# STM32L4A6xx register map
File version: 1.0
Registers are 32-bit, read-write, reset 0x0 unless marked. A register's access mark holds for its fields unless they carry their own. Offsets are from the block's base; [hi:lo] are bit positions; {n}, {i} and the like mark numbered series.

## DCMI
Base 0x50050000
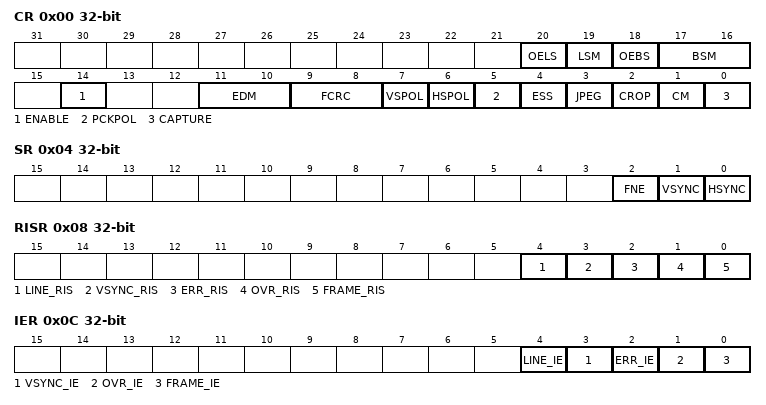
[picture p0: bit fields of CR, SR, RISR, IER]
0x00 CR — DCMI control register
  [20] OELS — DCMI Odd/Even Line Select (Line Select Start)
  [19] LSM — DCMI Line Select mode
  [18] OEBS — DCMI Odd/Even Byte Select (Byte Select Start)
  [17:16] BSM — DCMI Byte Select mode BSM[1:0]
  [14] ENABLE — DCMI DCMI enable
  [11:10] EDM — DCMI Extended data mode EDM[1:0]
  [9:8] FCRC — DCMI Frame capture rate control FCRC[1:0]
  [7] VSPOL — DCMI Vertical synchronization polarity
  [6] HSPOL — DCMI Horizontal synchronization polarity
  [5] PCKPOL — DCMI Pixel clock polarity
  [4] ESS — DCMI Embedded synchronization select
  [3] JPEG — DCMI JPEG format
  [2] CROP — DCMI Crop feature
  [1] CM — DCMI Capture mode
  [0] CAPTURE — DCMI Capture enable
0x04 SR — DCMI status register
  [2] FNE — DCMI FIFO not empty
  [1] VSYNC
  [0] HSYNC
0x08 RISR — DCMI raw interrupt status register
  [4] LINE_RIS — DCMI Line raw interrupt status
  [3] VSYNC_RIS — DCMI VSYNC raw interrupt status
  [2] ERR_RIS — DCMI Synchronization error raw interrupt status
  [1] OVR_RIS — DCMI Overrun raw interrupt status
  [0] FRAME_RIS — DCMI Capture complete raw interrupt status
0x0C IER — DCMI interrupt enable register
  [4] LINE_IE — DCMI Line interrupt enable
  [3] VSYNC_IE — DCMI VSYNC interrupt enable
  [2] ERR_IE — DCMI Synchronization error interrupt enable
  [1] OVR_IE — DCMI Overrun interrupt enable
  [0] FRAME_IE — DCMI Capture complete interrupt enable
0x0C IER_ALT (alternate view of IER) — DCMI interrupt enable register
  [4:0] INT_IE
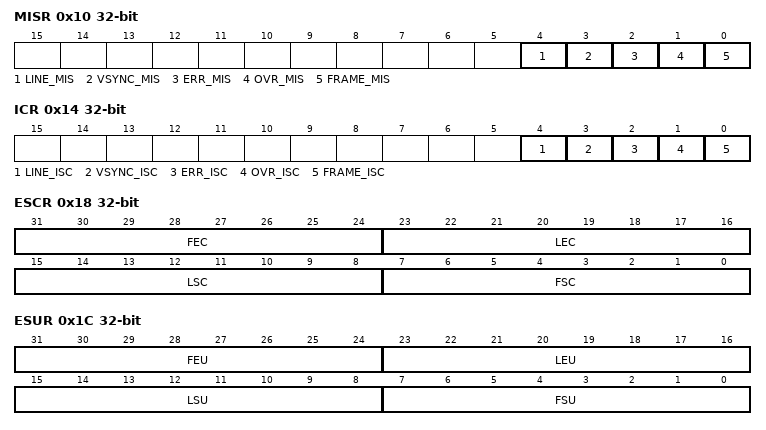
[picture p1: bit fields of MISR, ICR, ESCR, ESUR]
0x10 MISR — DCMI masked interrupt status register
  [4] LINE_MIS — DCMI Line masked interrupt status
  [3] VSYNC_MIS — DCMI VSYNC masked interrupt status
  [2] ERR_MIS — DCMI Synchronization error masked interrupt status
  [1] OVR_MIS — DCMI Overrun masked interrupt status
  [0] FRAME_MIS — DCMI Capture complete masked interrupt status
0x14 ICR — DCMI interrupt clear register
  [4] LINE_ISC — DCMI line interrupt status clear
  [3] VSYNC_ISC — DCMI Vertical synch interrupt status clear
  [2] ERR_ISC — DCMI Synchronization error interrupt status clear
  [1] OVR_ISC — DCMI Overrun interrupt status clear
  [0] FRAME_ISC — DCMI Capture complete interrupt status clear
0x18 ESCR — DCMI embedded synchronization code register
  [31:24] FEC — DCMI Frame end delimiter code FEC[7:0]
  [23:16] LEC — DCMI Line end delimiter code LEC[7:0]
  [15:8] LSC — DCMI Line start delimiter code LSC[7:0]
  [7:0] FSC — DCMI Frame start delimiter code FSC[7:0]
0x1C ESUR — DCMI embedded synchronization unmask register
  [31:24] FEU — DCMI Frame end delimiter unmask FEU[7:0]
  [23:16] LEU — DCMI Line end delimiter unmask LEU[7:0]
  [15:8] LSU — DCMI Line start delimiter unmask LSU[7:0]
  [7:0] FSU — DCMI Frame start delimiter unmask FSU[7:0]
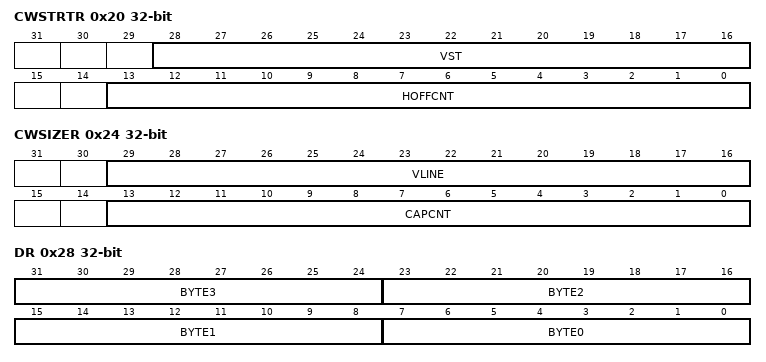
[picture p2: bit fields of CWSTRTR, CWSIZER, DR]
0x20 CWSTRTR — DCMI crop window start
  [28:16] VST — DCMI Vertical start line count VST[12:0]
  [13:0] HOFFCNT — DCMI Horizontal offset count HOFFCNT[13:0]
0x24 CWSIZER — DCMI crop window size
  [29:16] VLINE — DCMI Vertical line count VLINE[13:0]
  [13:0] CAPCNT — DCMI Capture count CAPCNT[13:0]
0x28 DR — DCMI data register
  [8n+7:8n] BYTE{n} (n=0..3) — DCMI Data byte {n} Byte{n}[7:0]

## AES — AES hardware accelerator
Base 0x50060000
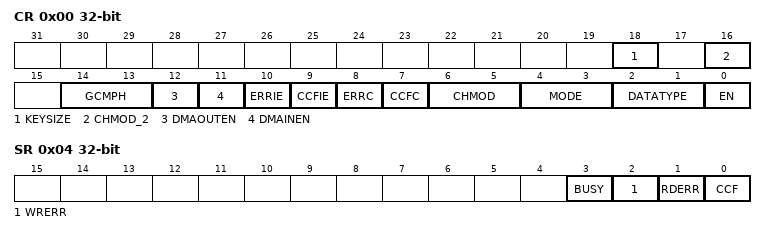
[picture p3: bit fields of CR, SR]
0x00 CR — AES control register
  [18] KEYSIZE — Key size selection
  [16] CHMOD_2 — AES Chaining Mode
  [14:13] GCMPH — GCM Phase
  [12] DMAOUTEN — Enable data output phase DMA management
  [11] DMAINEN — Enable data input phase DMA management
  [10] ERRIE — Error Interrupt Enable
  [9] CCFIE — Computation Complete Flag Interrupt Enable
  [8] ERRC — Error Clear
  [7] CCFC — Computation Complete Flag Clear
  [6:5] CHMOD — AES Chaining Mode
  [4:3] MODE — AES Mode Of Operation
  [2:1] DATATYPE — Data type selection
  [0] EN — AES Enable
0x04 SR — AES status register
  [3] BUSY — Busy Flag
  [2] WRERR — Write Error Flag
  [1] RDERR — Read Error Flag
  [0] CCF — Computation Complete Flag
0x08 DINR — AES data input register
  [31:0] DINR — AES Data Input Register
0x0C DOUTR — AES data output register
  [31:0] DOUTR — AES Data Output Register
{0x10+4i} KEYR{i} (i=0..3) — AES key register {i}
  [31:0] KEYR{i} — AES Key Register {i}
{0x20+4i} IVR{i} (i=0..3) — AES initialization vector register {i}
  [31:0] IVR{i} — AES Initialization Vector Register {i}
{0x20+4i} KEYR{i} (i=4..7) — AES key register {i}
  [31:0] KEYR{i} — AES Key Register {i}
{0x40+4i} SUSP{i}R (i=0..7) — AES Suspend register {i}
  [31:0] SUSP{i}R — AES Suspend registers {i}
